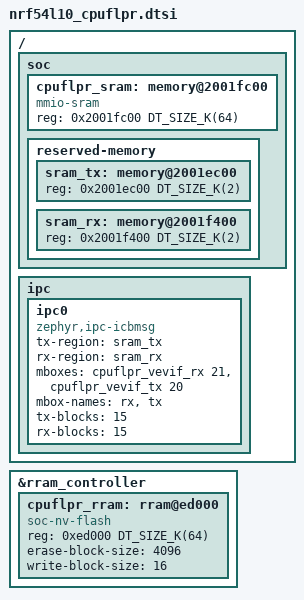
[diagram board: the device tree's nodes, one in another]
/*
 * Copyright (c) 2024 Nordic Semiconductor ASA
 *
 * SPDX-License-Identifier: Apache-2.0
 */

#include <nordic/nrf54l10.dtsi>
#include <riscv/nordic/nrf54l_05_10_15_cpuflpr.dtsi>

/* 123 (APP RAM) + 4 (IPC memory) + 64 (FLPR RAM) + 1 (FLPR hibernation) = 192KB */
/ {
	soc {
		cpuflpr_sram: memory@2001fc00 {
			compatible = "mmio-sram";
			reg = <0x2001fc00 DT_SIZE_K(64)>;
			#address-cells = <1>;
			#size-cells = <1>;
			ranges = <0x0 0x2001fc00 DT_SIZE_K(64)>;
		};

		reserved-memory {
			#address-cells = <1>;
			#size-cells = <1>;

			sram_tx: memory@2001ec00 {
				reg = <0x2001ec00 DT_SIZE_K(2)>;
			};

			sram_rx: memory@2001f400 {
				reg = <0x2001f400 DT_SIZE_K(2)>;
			};
		};
	};

	ipc {
		ipc0: ipc0 {
			compatible = "zephyr,ipc-icbmsg";
			tx-region = <&sram_tx>;
			rx-region = <&sram_rx>;
			mboxes = <&cpuflpr_vevif_rx 21>, <&cpuflpr_vevif_tx 20>;
			mbox-names = "rx", "tx";
			tx-blocks = <15>;
			rx-blocks = <15>;
			status = "okay";
		};
	};
};

&rram_controller {
	cpuflpr_rram: rram@ed000 {
		compatible = "soc-nv-flash";
		reg = <0xed000 DT_SIZE_K(64)>;
		ranges = <0x0 0xed000 DT_SIZE_K(64)>;
		#address-cells = <1>;
		#size-cells = <1>;
		erase-block-size = <4096>;
		write-block-size = <16>;
	};
};
